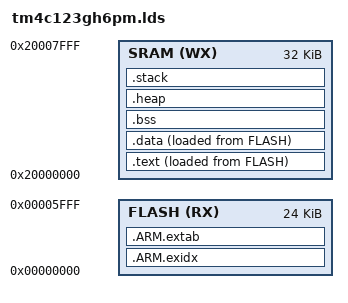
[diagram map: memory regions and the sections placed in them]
/******************************************************************************
 *
 * Default Linker script for the Texas Instruments TM4C123GH6PM
 *
 * This is derived from revision 15071 of the TivaWare Library.
 *
 *****************************************************************************/

MEMORY
{
    FLASH (RX) : ORIGIN = 0x00000000, LENGTH = 0x00006000
    SRAM (WX)  : ORIGIN = 0x20000000, LENGTH = 0x00008000
}

SECTIONS {

    .text : {
    	__code_load__ = LOADADDR (.text);
        __code_start__ = .;
        CREATE_OBJECT_SYMBOLS
        KEEP (*(.intvecs))
        *(.text)
        *(.text.*)
        *(.rodata)
        *(.rodata*)
        . = ALIGN(0x4);
        KEEP (*(.ctors))
        . = ALIGN(0x4);
        KEEP (*(.dtors))
        . = ALIGN(0x4);
        __init_array_start = .;
        KEEP (*(.init_array*))
        __init_array_end = .;
        *(.init)
        *(.fini*)
         __code_end__ = .;
    } > SRAM AT> FLASH

    PROVIDE (__etext = .);
    PROVIDE (_etext = .);
    PROVIDE (etext = .);

    .data : ALIGN (4) {
        __data_load__ = LOADADDR (.data);
        __data_start__ = .;
        *(.data)
        *(.data*)
        . = ALIGN (4);
        __data_end__ = .;
    } > SRAM AT> FLASH

    .ARM.exidx : {
        __exidx_start = .;
        *(.ARM.exidx* .gnu.linkonce.armexidx.*)
        __exidx_end = .;
    } > FLASH

    .ARM.extab : {
        *(.ARM.extab* .gnu.linkonce.armextab.*)
    } > FLASH

    .bss : {
        __bss_start__ = .;
        *(.shbss)
        *(.bss)
        *(.bss.*)
        *(COMMON)
        . = ALIGN (4);
        __bss_end__ = .;
    } > SRAM

    .heap : {
        __heap_start__ = .;
        end = __heap_start__;
        _end = end;
        __end = end;
        KEEP(*(.heap))
        __heap_end__ = .;
        __HeapLimit = __heap_end__;
    } > SRAM

    .stack : ALIGN(0x8) {
        _stack = .;
        __stack = .;
        KEEP(*(.stack))
    } > SRAM
}
